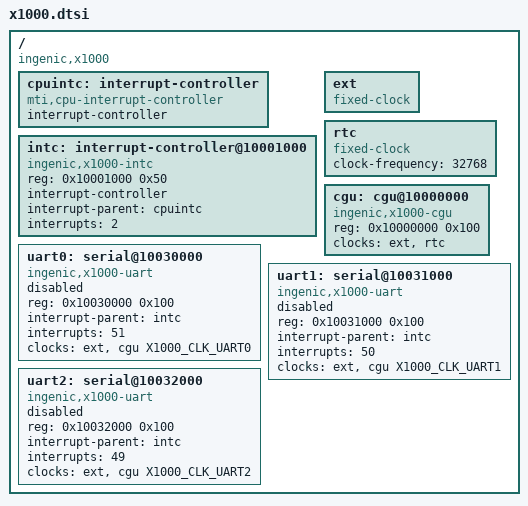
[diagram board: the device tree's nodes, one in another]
/*
 * Copyright (C) 2016 PrasannaKumar Muralidharan <prasannatsmkumar@gmail.com>
 *
 * SPDX-License-Identifier: GPL-2.0
 */

#include <dt-bindings/clock/x1000-cgu.h>

/ {
	#address-cells = <1>;
	#size-cells = <1>;
	compatible = "ingenic,x1000";

	cpuintc: interrupt-controller {
		#address-cells = <0>;
		#interrupt-cells = <1>;
		interrupt-controller;
		compatible = "mti,cpu-interrupt-controller";
	};

	intc: interrupt-controller@10001000 {
		compatible = "ingenic,x1000-intc", "ingenic,jz4780-intc";
		reg = <0x10001000 0x50>;

		interrupt-controller;
		#interrupt-cells = <1>;

		interrupt-parent = <&cpuintc>;
		interrupts = <2>;
	};

	ext: ext {
		compatible = "fixed-clock";
		#clock-cells = <0>;
	};

	rtc: rtc {
		compatible = "fixed-clock";
		#clock-cells = <0>;
		clock-frequency = <32768>;
	};

	cgu: cgu@10000000 {
		compatible = "ingenic,x1000-cgu";
		reg = <0x10000000 0x100>;

		clocks = <&ext>, <&rtc>;
		clock-names = "ext", "rtc";

		#clock-cells = <1>;
	};

	uart0: serial@10030000 {
		compatible = "ingenic,x1000-uart", "ingenic,jz4780-uart";
		reg = <0x10030000 0x100>;

		interrupt-parent = <&intc>;
		interrupts = <51>;

		clocks = <&ext>, <&cgu X1000_CLK_UART0>;
		clock-names = "baud", "module";

		status = "disabled";
	};

	uart1: serial@10031000 {
		compatible = "ingenic,x1000-uart", "ingenic,jz4780-uart";
		reg = <0x10031000 0x100>;

		interrupt-parent = <&intc>;
		interrupts = <50>;

		clocks = <&ext>, <&cgu X1000_CLK_UART1>;
		clock-names = "baud", "module";

		status = "disabled";
	};

	uart2: serial@10032000 {
		compatible = "ingenic,x1000-uart", "ingenic,jz4780-uart";
		reg = <0x10032000 0x100>;

		interrupt-parent = <&intc>;
		interrupts = <49>;

		clocks = <&ext>, <&cgu X1000_CLK_UART2>;
		clock-names = "baud", "module";

		status = "disabled";
	};
};
